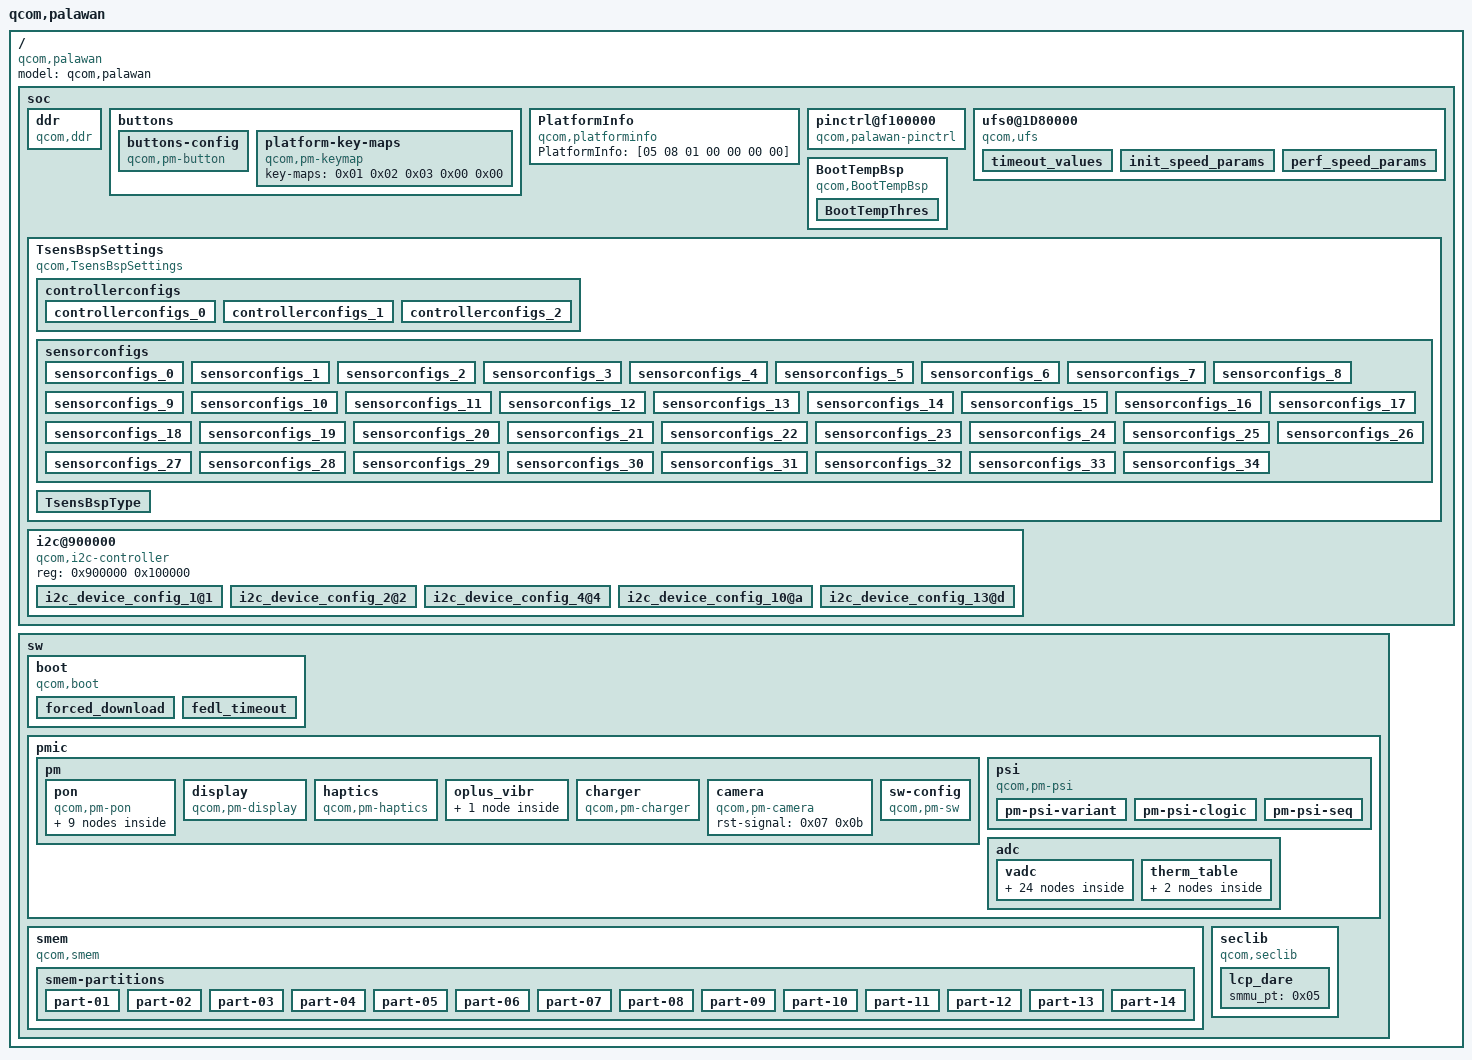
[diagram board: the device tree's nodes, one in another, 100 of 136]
/dts-v1/;

/ {
	compatible = "qcom,palawan";
	model = "qcom,palawan";
	#address-cells = <0x02>;
	#size-cells = <0x02>;

	soc {
		#address-cells = <0x01>;
		#size-cells = <0x01>;
		phandle = <0x02>;

		ddr {
			compatible = "qcom,ddr";
			print_severity = <0x2012>;
			ddr_log_level = <0x00>;
			ddr_trng_always_en = <0x00>;
			extnd_term_log_flag = <0x01>;
			ddr_tr_led_flag = <0x00>;
			ddr_boot_freq = <0x1fef00>;
		};

		buttons {
			phandle = <0x03>;

			buttons-config {
				compatible = "qcom,pm-button";
				gpio-configs = <0x00 0x01 0x01 0x05 0x00 0x01 0x00 0x00>;
			};

			platform-key-maps {
				compatible = "qcom,pm-keymap";
				key-maps = <0x01 0x02 0x03 0x00 0x00>;
			};
		};

		PlatformInfo {
			compatible = "qcom,platforminfo";
			PlatformInfo = [05 08 01 00 00 00 00];
		};

		pinctrl@f100000 {
			compatible = "qcom,palawan-pinctrl";
			reg = <0xf100000 0x100000>;
			ngpios = <0xb2>;
			width = <0x1000>;
			id = <0x00>;
			version = <0x01>;
			gpio-controller;
			#gpio-cells = <0x02>;
			phandle = <0x04>;
		};

		ufs0@1D80000 {
			compatible = "qcom,ufs";
			reg = <0x1d80000 0x7000>;
			EnableLogging = [00];
			FUA_Value = [01];
			LinkStartupRetryCount = [05];
			BatteryThresholdMv = <0xe10>;
			phandle = <0x05>;

			timeout_values {
				fDeviceInitTimeoutUs = <0x2625a0>;
				UTRDPollTimeoutUs = <0x1c9c380>;
			};

			init_speed_params {
				EnableHighSpeed = [01];
				NumGears = [05];
				NumLanes = [02];
				Rate = [02];
			};

			perf_speed_params {
				EnableHighSpeed = [01];
				NumGears = [05];
				NumLanes = [02];
				Rate = [02];
			};
		};

		BootTempBsp {
			compatible = "qcom,BootTempBsp";

			BootTempThres {
				nUpperThresholdDegC = <0x96>;
				nLowerThresholdDegC = <0xffffff6a>;
				uMaxNumIterations = <0x28>;
				uWaitPerIterationMicroSec = <0x7a120>;
				uSensor = <0x00>;
			};
		};

		TsensBspSettings {
			compatible = "qcom,TsensBspSettings";

			controllerconfigs {

				controllerconfigs_0 {
					pucTsensSROTPhys = <0x00 0xc222000>;
					pucTsensTMPhys = <0x00 0xc228000>;
					pauTbcbReqs = <0x00 0x00>;
					uTsensSROTSize = <0x1000>;
					uTsensTMSize = <0x1000>;
					uNumTbcbClients = <0x00>;
					uPeriodActive = <0x00>;
					uPeriodSleep = <0x40>;
					uTSControl = <0x20000000>;
					uTSConfig = <0x00>;
					uSidebandEnMask = <0x3fff>;
					uWatchdogLoadVal = <0x267a>;
					uZeroCEnMask = <0x3fff>;
					nsZeroCSetDeciDegC = [00 32];
					nsZeroCResetDeciDegC = [00 64];
					bPSHoldResetEn = [01];
					bAutoAdjustPeriod = [01];
					bStandAlone = [00];
					bPWMEn = [00];
					bWatchdogEn = [01];
					bWatchdogResetEn = [01];
				};

				controllerconfigs_1 {
					pucTsensSROTPhys = <0x00 0xc223000>;
					pucTsensTMPhys = <0x00 0xc229000>;
					pauTbcbReqs = <0x00 0x00>;
					uTsensSROTSize = <0x1000>;
					uTsensTMSize = <0x1000>;
					uNumTbcbClients = <0x00>;
					uPeriodActive = <0x00>;
					uPeriodSleep = <0x40>;
					uTSControl = <0x20000000>;
					uTSConfig = <0x00>;
					uSidebandEnMask = <0xffff>;
					uWatchdogLoadVal = <0x267a>;
					uZeroCEnMask = <0xffff>;
					nsZeroCSetDeciDegC = [00 32];
					nsZeroCResetDeciDegC = [00 64];
					bPSHoldResetEn = [01];
					bAutoAdjustPeriod = [01];
					bStandAlone = [00];
					bPWMEn = [00];
					bWatchdogEn = [01];
					bWatchdogResetEn = [01];
				};

				controllerconfigs_2 {
					pucTsensSROTPhys = <0x00 0xc224000>;
					pucTsensTMPhys = <0x00 0xc22a000>;
					pauTbcbReqs = <0x00 0x00>;
					uTsensSROTSize = <0x1000>;
					uTsensTMSize = <0x1000>;
					uNumTbcbClients = <0x00>;
					uPeriodActive = <0x00>;
					uPeriodSleep = <0x40>;
					uTSControl = <0x20000000>;
					uTSConfig = <0x00>;
					uSidebandEnMask = <0x1f>;
					uWatchdogLoadVal = <0x267a>;
					uZeroCEnMask = <0x1f>;
					nsZeroCSetDeciDegC = [00 32];
					nsZeroCResetDeciDegC = [00 64];
					bPSHoldResetEn = [01];
					bAutoAdjustPeriod = [01];
					bStandAlone = [00];
					bPWMEn = [00];
					bWatchdogEn = [01];
					bWatchdogResetEn = [01];
				};
			};

			sensorconfigs {

				sensorconfigs_0 {
					eCal = <0x00>;
					nsCalPoint1CodeDefault = [01 e0];
					nsCalPoint2CodeDefault = [02 ca];
					nsThresholdMinDeciDegC = [7f ff];
					nsThresholdLowerDeciDegC = [7f ff];
					nsThresholdUpperDeciDegC = [7f ff];
					nsThresholdCriticalDeciDegC = [7f ff];
					nsThresholdMaxDeciDegC = [04 b0];
					controller = [00];
					ucChannel = [00];
					ucSensorID = [00];
					ucFuseIdx = [00];
				};

				sensorconfigs_1 {
					eCal = <0x00>;
					nsCalPoint1CodeDefault = [01 e0];
					nsCalPoint2CodeDefault = [02 ca];
					nsThresholdMinDeciDegC = [7f ff];
					nsThresholdLowerDeciDegC = [7f ff];
					nsThresholdUpperDeciDegC = [7f ff];
					nsThresholdCriticalDeciDegC = [7f ff];
					nsThresholdMaxDeciDegC = [04 b0];
					controller = [00];
					ucChannel = [01];
					ucSensorID = [01];
					ucFuseIdx = [01];
				};

				sensorconfigs_2 {
					eCal = <0x00>;
					nsCalPoint1CodeDefault = [01 e0];
					nsCalPoint2CodeDefault = [02 ca];
					nsThresholdMinDeciDegC = [7f ff];
					nsThresholdLowerDeciDegC = [7f ff];
					nsThresholdUpperDeciDegC = [7f ff];
					nsThresholdCriticalDeciDegC = [7f ff];
					nsThresholdMaxDeciDegC = [04 b0];
					controller = [00];
					ucChannel = [02];
					ucSensorID = [02];
					ucFuseIdx = [02];
				};

				sensorconfigs_3 {
					eCal = <0x00>;
					nsCalPoint1CodeDefault = [01 e0];
					nsCalPoint2CodeDefault = [02 ca];
					nsThresholdMinDeciDegC = [7f ff];
					nsThresholdLowerDeciDegC = [7f ff];
					nsThresholdUpperDeciDegC = [7f ff];
					nsThresholdCriticalDeciDegC = [7f ff];
					nsThresholdMaxDeciDegC = [04 b0];
					controller = [00];
					ucChannel = [03];
					ucSensorID = [03];
					ucFuseIdx = [03];
				};

				sensorconfigs_4 {
					eCal = <0x00>;
					nsCalPoint1CodeDefault = [01 e0];
					nsCalPoint2CodeDefault = [02 ca];
					nsThresholdMinDeciDegC = [7f ff];
					nsThresholdLowerDeciDegC = [7f ff];
					nsThresholdUpperDeciDegC = [7f ff];
					nsThresholdCriticalDeciDegC = [7f ff];
					nsThresholdMaxDeciDegC = [04 b0];
					controller = [00];
					ucChannel = [04];
					ucSensorID = [04];
					ucFuseIdx = [04];
				};

				sensorconfigs_5 {
					eCal = <0x00>;
					nsCalPoint1CodeDefault = [01 e0];
					nsCalPoint2CodeDefault = [02 ca];
					nsThresholdMinDeciDegC = [7f ff];
					nsThresholdLowerDeciDegC = [7f ff];
					nsThresholdUpperDeciDegC = [7f ff];
					nsThresholdCriticalDeciDegC = [7f ff];
					nsThresholdMaxDeciDegC = [04 b0];
					controller = [00];
					ucChannel = [05];
					ucSensorID = [05];
					ucFuseIdx = [05];
				};

				sensorconfigs_6 {
					eCal = <0x00>;
					nsCalPoint1CodeDefault = [01 e0];
					nsCalPoint2CodeDefault = [02 ca];
					nsThresholdMinDeciDegC = [7f ff];
					nsThresholdLowerDeciDegC = [7f ff];
					nsThresholdUpperDeciDegC = [7f ff];
					nsThresholdCriticalDeciDegC = [7f ff];
					nsThresholdMaxDeciDegC = [04 b0];
					controller = [00];
					ucChannel = [06];
					ucSensorID = [06];
					ucFuseIdx = [06];
				};

				sensorconfigs_7 {
					eCal = <0x00>;
					nsCalPoint1CodeDefault = [01 e0];
					nsCalPoint2CodeDefault = [02 ca];
					nsThresholdMinDeciDegC = [7f ff];
					nsThresholdLowerDeciDegC = [7f ff];
					nsThresholdUpperDeciDegC = [7f ff];
					nsThresholdCriticalDeciDegC = [7f ff];
					nsThresholdMaxDeciDegC = [04 b0];
					controller = [00];
					ucChannel = [07];
					ucSensorID = [07];
					ucFuseIdx = [07];
				};

				sensorconfigs_8 {
					eCal = <0x00>;
					nsCalPoint1CodeDefault = [01 e0];
					nsCalPoint2CodeDefault = [02 ca];
					nsThresholdMinDeciDegC = [7f ff];
					nsThresholdLowerDeciDegC = [7f ff];
					nsThresholdUpperDeciDegC = [7f ff];
					nsThresholdCriticalDeciDegC = [7f ff];
					nsThresholdMaxDeciDegC = [04 b0];
					controller = [00];
					ucChannel = [08];
					ucSensorID = [08];
					ucFuseIdx = [08];
				};

				sensorconfigs_9 {
					eCal = <0x00>;
					nsCalPoint1CodeDefault = [01 e0];
					nsCalPoint2CodeDefault = [02 ca];
					nsThresholdMinDeciDegC = [7f ff];
					nsThresholdLowerDeciDegC = [7f ff];
					nsThresholdUpperDeciDegC = [7f ff];
					nsThresholdCriticalDeciDegC = [7f ff];
					nsThresholdMaxDeciDegC = [04 b0];
					controller = [00];
					ucChannel = [09];
					ucSensorID = [09];
					ucFuseIdx = [09];
				};

				sensorconfigs_10 {
					eCal = <0x00>;
					nsCalPoint1CodeDefault = [01 e0];
					nsCalPoint2CodeDefault = [02 ca];
					nsThresholdMinDeciDegC = [7f ff];
					nsThresholdLowerDeciDegC = [7f ff];
					nsThresholdUpperDeciDegC = [7f ff];
					nsThresholdCriticalDeciDegC = [7f ff];
					nsThresholdMaxDeciDegC = [04 b0];
					controller = [00];
					ucChannel = [0a];
					ucSensorID = [0a];
					ucFuseIdx = [0a];
				};

				sensorconfigs_11 {
					eCal = <0x00>;
					nsCalPoint1CodeDefault = [01 e0];
					nsCalPoint2CodeDefault = [02 ca];
					nsThresholdMinDeciDegC = [7f ff];
					nsThresholdLowerDeciDegC = [7f ff];
					nsThresholdUpperDeciDegC = [7f ff];
					nsThresholdCriticalDeciDegC = [7f ff];
					nsThresholdMaxDeciDegC = [04 b0];
					controller = [00];
					ucChannel = [0b];
					ucSensorID = [0b];
					ucFuseIdx = [0b];
				};

				sensorconfigs_12 {
					eCal = <0x00>;
					nsCalPoint1CodeDefault = [01 e0];
					nsCalPoint2CodeDefault = [02 ca];
					nsThresholdMinDeciDegC = [7f ff];
					nsThresholdLowerDeciDegC = [7f ff];
					nsThresholdUpperDeciDegC = [7f ff];
					nsThresholdCriticalDeciDegC = [7f ff];
					nsThresholdMaxDeciDegC = [04 b0];
					controller = [00];
					ucChannel = [0c];
					ucSensorID = [0c];
					ucFuseIdx = [0c];
				};

				sensorconfigs_13 {
					eCal = <0x00>;
					nsCalPoint1CodeDefault = [01 e0];
					nsCalPoint2CodeDefault = [02 ca];
					nsThresholdMinDeciDegC = [7f ff];
					nsThresholdLowerDeciDegC = [7f ff];
					nsThresholdUpperDeciDegC = [7f ff];
					nsThresholdCriticalDeciDegC = [7f ff];
					nsThresholdMaxDeciDegC = [04 b0];
					controller = [00];
					ucChannel = [0d];
					ucSensorID = [0d];
					ucFuseIdx = [0d];
				};

				sensorconfigs_14 {
					eCal = <0x00>;
					nsCalPoint1CodeDefault = [01 e0];
					nsCalPoint2CodeDefault = [02 ca];
					nsThresholdMinDeciDegC = [7f ff];
					nsThresholdLowerDeciDegC = [7f ff];
					nsThresholdUpperDeciDegC = [7f ff];
					nsThresholdCriticalDeciDegC = [7f ff];
					nsThresholdMaxDeciDegC = [04 b0];
					controller = [01];
					ucChannel = [00];
					ucSensorID = [00];
					ucFuseIdx = [0e];
				};

				sensorconfigs_15 {
					eCal = <0x00>;
					nsCalPoint1CodeDefault = [01 e0];
					nsCalPoint2CodeDefault = [02 ca];
					nsThresholdMinDeciDegC = [7f ff];
					nsThresholdLowerDeciDegC = [7f ff];
					nsThresholdUpperDeciDegC = [7f ff];
					nsThresholdCriticalDeciDegC = [7f ff];
					nsThresholdMaxDeciDegC = [04 b0];
					controller = [01];
					ucChannel = [01];
					ucSensorID = [01];
					ucFuseIdx = [0f];
				};

				sensorconfigs_16 {
					eCal = <0x00>;
					nsCalPoint1CodeDefault = [01 e0];
					nsCalPoint2CodeDefault = [02 ca];
					nsThresholdMinDeciDegC = [7f ff];
					nsThresholdLowerDeciDegC = [7f ff];
					nsThresholdUpperDeciDegC = [7f ff];
					nsThresholdCriticalDeciDegC = [7f ff];
					nsThresholdMaxDeciDegC = [04 b0];
					controller = [01];
					ucChannel = [02];
					ucSensorID = [02];
					ucFuseIdx = [10];
				};

				sensorconfigs_17 {
					eCal = <0x00>;
					nsCalPoint1CodeDefault = [01 e0];
					nsCalPoint2CodeDefault = [02 ca];
					nsThresholdMinDeciDegC = [7f ff];
					nsThresholdLowerDeciDegC = [7f ff];
					nsThresholdUpperDeciDegC = [7f ff];
					nsThresholdCriticalDeciDegC = [7f ff];
					nsThresholdMaxDeciDegC = [04 b0];
					controller = [01];
					ucChannel = [03];
					ucSensorID = [03];
					ucFuseIdx = [11];
				};

				sensorconfigs_18 {
					eCal = <0x00>;
					nsCalPoint1CodeDefault = [01 e0];
					nsCalPoint2CodeDefault = [02 ca];
					nsThresholdMinDeciDegC = [7f ff];
					nsThresholdLowerDeciDegC = [7f ff];
					nsThresholdUpperDeciDegC = [7f ff];
					nsThresholdCriticalDeciDegC = [7f ff];
					nsThresholdMaxDeciDegC = [04 b0];
					controller = [01];
					ucChannel = [04];
					ucSensorID = [04];
					ucFuseIdx = [12];
				};

				sensorconfigs_19 {
					eCal = <0x00>;
					nsCalPoint1CodeDefault = [01 e0];
					nsCalPoint2CodeDefault = [02 ca];
					nsThresholdMinDeciDegC = [7f ff];
					nsThresholdLowerDeciDegC = [7f ff];
					nsThresholdUpperDeciDegC = [7f ff];
					nsThresholdCriticalDeciDegC = [7f ff];
					nsThresholdMaxDeciDegC = [04 b0];
					controller = [01];
					ucChannel = [05];
					ucSensorID = [05];
					ucFuseIdx = [13];
				};

				sensorconfigs_20 {
					eCal = <0x00>;
					nsCalPoint1CodeDefault = [01 e0];
					nsCalPoint2CodeDefault = [02 ca];
					nsThresholdMinDeciDegC = [7f ff];
					nsThresholdLowerDeciDegC = [7f ff];
					nsThresholdUpperDeciDegC = [7f ff];
					nsThresholdCriticalDeciDegC = [7f ff];
					nsThresholdMaxDeciDegC = [04 b0];
					controller = [01];
					ucChannel = [06];
					ucSensorID = [06];
					ucFuseIdx = [14];
				};

				sensorconfigs_21 {
					eCal = <0x00>;
					nsCalPoint1CodeDefault = [01 e0];
					nsCalPoint2CodeDefault = [02 ca];
					nsThresholdMinDeciDegC = [7f ff];
					nsThresholdLowerDeciDegC = [7f ff];
					nsThresholdUpperDeciDegC = [7f ff];
					nsThresholdCriticalDeciDegC = [7f ff];
					nsThresholdMaxDeciDegC = [04 b0];
					controller = [01];
					ucChannel = [07];
					ucSensorID = [07];
					ucFuseIdx = [15];
				};

				sensorconfigs_22 {
					eCal = <0x00>;
					nsCalPoint1CodeDefault = [01 e0];
					nsCalPoint2CodeDefault = [02 ca];
					nsThresholdMinDeciDegC = [7f ff];
					nsThresholdLowerDeciDegC = [7f ff];
					nsThresholdUpperDeciDegC = [7f ff];
					nsThresholdCriticalDeciDegC = [7f ff];
					nsThresholdMaxDeciDegC = [04 b0];
					controller = [01];
					ucChannel = [08];
					ucSensorID = [08];
					ucFuseIdx = [16];
				};

				sensorconfigs_23 {
					eCal = <0x00>;
					nsCalPoint1CodeDefault = [01 e0];
					nsCalPoint2CodeDefault = [02 ca];
					nsThresholdMinDeciDegC = [7f ff];
					nsThresholdLowerDeciDegC = [7f ff];
					nsThresholdUpperDeciDegC = [7f ff];
					nsThresholdCriticalDeciDegC = [7f ff];
					nsThresholdMaxDeciDegC = [04 b0];
					controller = [01];
					ucChannel = [09];
					ucSensorID = [09];
					ucFuseIdx = [17];
				};

				sensorconfigs_24 {
					eCal = <0x00>;
					nsCalPoint1CodeDefault = [01 e0];
					nsCalPoint2CodeDefault = [02 ca];
					nsThresholdMinDeciDegC = [7f ff];
					nsThresholdLowerDeciDegC = [7f ff];
					nsThresholdUpperDeciDegC = [7f ff];
					nsThresholdCriticalDeciDegC = [7f ff];
					nsThresholdMaxDeciDegC = [04 b0];
					controller = [01];
					ucChannel = [0a];
					ucSensorID = [0a];
					ucFuseIdx = [18];
				};

				sensorconfigs_25 {
					eCal = <0x00>;
					nsCalPoint1CodeDefault = [01 e0];
					nsCalPoint2CodeDefault = [02 ca];
					nsThresholdMinDeciDegC = [7f ff];
					nsThresholdLowerDeciDegC = [7f ff];
					nsThresholdUpperDeciDegC = [7f ff];
					nsThresholdCriticalDeciDegC = [7f ff];
					nsThresholdMaxDeciDegC = [04 b0];
					controller = [01];
					ucChannel = [0b];
					ucSensorID = [0b];
					ucFuseIdx = [19];
				};

				sensorconfigs_26 {
					eCal = <0x00>;
					nsCalPoint1CodeDefault = [01 e0];
					nsCalPoint2CodeDefault = [02 ca];
					nsThresholdMinDeciDegC = [7f ff];
					nsThresholdLowerDeciDegC = [7f ff];
					nsThresholdUpperDeciDegC = [7f ff];
					nsThresholdCriticalDeciDegC = [7f ff];
					nsThresholdMaxDeciDegC = [04 b0];
					controller = [01];
					ucChannel = [0c];
					ucSensorID = [0c];
					ucFuseIdx = [1a];
				};

				sensorconfigs_27 {
					eCal = <0x00>;
					nsCalPoint1CodeDefault = [01 e0];
					nsCalPoint2CodeDefault = [02 ca];
					nsThresholdMinDeciDegC = [7f ff];
					nsThresholdLowerDeciDegC = [7f ff];
					nsThresholdUpperDeciDegC = [7f ff];
					nsThresholdCriticalDeciDegC = [7f ff];
					nsThresholdMaxDeciDegC = [04 b0];
					controller = [01];
					ucChannel = [0d];
					ucSensorID = [0d];
					ucFuseIdx = [1b];
				};

				sensorconfigs_28 {
					eCal = <0x00>;
					nsCalPoint1CodeDefault = [01 e0];
					nsCalPoint2CodeDefault = [02 ca];
					nsThresholdMinDeciDegC = [7f ff];
					nsThresholdLowerDeciDegC = [7f ff];
					nsThresholdUpperDeciDegC = [7f ff];
					nsThresholdCriticalDeciDegC = [7f ff];
					nsThresholdMaxDeciDegC = [04 b0];
					controller = [01];
					ucChannel = [0e];
					ucSensorID = [0e];
					ucFuseIdx = [1c];
				};

				sensorconfigs_29 {
					eCal = <0x00>;
					nsCalPoint1CodeDefault = [01 e0];
					nsCalPoint2CodeDefault = [02 ca];
					nsThresholdMinDeciDegC = [7f ff];
					nsThresholdLowerDeciDegC = [7f ff];
					nsThresholdUpperDeciDegC = [7f ff];
					nsThresholdCriticalDeciDegC = [7f ff];
					nsThresholdMaxDeciDegC = [04 b0];
					controller = [01];
					ucChannel = [0f];
					ucSensorID = [0f];
					ucFuseIdx = [1d];
				};

				sensorconfigs_30 {
					eCal = <0x00>;
					nsCalPoint1CodeDefault = [01 e0];
					nsCalPoint2CodeDefault = [02 ca];
					nsThresholdMinDeciDegC = [7f ff];
					nsThresholdLowerDeciDegC = [7f ff];
					nsThresholdUpperDeciDegC = [7f ff];
					nsThresholdCriticalDeciDegC = [7f ff];
					nsThresholdMaxDeciDegC = [04 b0];
					controller = [02];
					ucChannel = [00];
					ucSensorID = [00];
					ucFuseIdx = [1e];
				};

				sensorconfigs_31 {
					eCal = <0x00>;
					nsCalPoint1CodeDefault = [01 e0];
					nsCalPoint2CodeDefault = [02 ca];
					nsThresholdMinDeciDegC = [7f ff];
					nsThresholdLowerDeciDegC = [7f ff];
					nsThresholdUpperDeciDegC = [7f ff];
					nsThresholdCriticalDeciDegC = [7f ff];
					nsThresholdMaxDeciDegC = [04 b0];
					controller = [02];
					ucChannel = [01];
					ucSensorID = [01];
					ucFuseIdx = [1f];
				};

				sensorconfigs_32 {
					eCal = <0x00>;
					nsCalPoint1CodeDefault = [01 e0];
					nsCalPoint2CodeDefault = [02 ca];
					nsThresholdMinDeciDegC = [7f ff];
					nsThresholdLowerDeciDegC = [7f ff];
					nsThresholdUpperDeciDegC = [7f ff];
					nsThresholdCriticalDeciDegC = [7f ff];
					nsThresholdMaxDeciDegC = [04 b0];
					controller = [02];
					ucChannel = [02];
					ucSensorID = [02];
					ucFuseIdx = [20];
				};

				sensorconfigs_33 {
					eCal = <0x00>;
					nsCalPoint1CodeDefault = [01 e0];
					nsCalPoint2CodeDefault = [02 ca];
					nsThresholdMinDeciDegC = [7f ff];
					nsThresholdLowerDeciDegC = [7f ff];
					nsThresholdUpperDeciDegC = [7f ff];
					nsThresholdCriticalDeciDegC = [7f ff];
					nsThresholdMaxDeciDegC = [04 b0];
					controller = [02];
					ucChannel = [03];
					ucSensorID = [03];
					ucFuseIdx = [21];
				};

				sensorconfigs_34 {
					eCal = <0x00>;
					nsCalPoint1CodeDefault = [01 e0];
					nsCalPoint2CodeDefault = [02 ca];
					nsThresholdMinDeciDegC = [7f ff];
					nsThresholdLowerDeciDegC = [7f ff];
					nsThresholdUpperDeciDegC = [7f ff];
					nsThresholdCriticalDeciDegC = [7f ff];
					nsThresholdMaxDeciDegC = [04 b0];
					controller = [02];
					ucChannel = [04];
					ucSensorID = [04];
					ucFuseIdx = [22];
				};
			};

			TsensBspType {
				uNumControllers = <0x03>;
				uNumSensors = <0x23>;
				uSensorConvTime_us = <0x1e>;
				nCalPoint1DeciDegC = <0x12c>;
				nCalPoint2DeciDegC = <0x4b0>;
				uShift = <0x0a>;
			};
		};

		i2c@900000 {
			#address-cells = <0x01>;
			#size-cells = <0x00>;
			compatible = "qcom,i2c-controller";
			reg = <0x900000 0x100000>;

			i2c_device_config_1@1 {
				reg = <0x01>;
				status = "okay";
				core_base_addr = <0xa00000>;
				common_base_addr = <0xac0000>;
				core_offset = <0x80000>;
				qupv3_instance = [00];
				core_index = [01];
				se_index = [00];
				gpi_index = [00];
				core_irq = [00];
				polled_mode = [01];
				i2c_hub = [00];
				min_data_length_for_dma = [00];
				scl_encoding = <0x40018351>;
				sda_encoding = <0x40018341>;
				tcsr_reg_offset = <0x00>;
				tcsr_base_addr = <0x1fc0000>;
				tcsr_reg_value = <0x00>;
				se_clock = "gcc_qupv3_wrap0_s0_clk";
			};

			i2c_device_config_2@2 {
				reg = <0x02>;
				status = "okay";
				core_base_addr = <0xa00000>;
				common_base_addr = <0xac0000>;
				core_offset = "", "\b@";
				qupv3_instance = [00];
				core_index = [02];
				se_index = [01];
				gpi_index = [00];
				core_irq = [00];
				polled_mode = [01];
				i2c_hub = [00];
				min_data_length_for_dma = [00];
				scl_encoding = <0x18051>;
				sda_encoding = <0x18041>;
				tcsr_reg_offset = <0x00>;
				tcsr_base_addr = <0x1fc0000>;
				tcsr_reg_value = <0x00>;
				se_clock = "gcc_qupv3_wrap0_s1_clk";
			};

			i2c_device_config_4@4 {
				reg = <0x04>;
				status = "okay";
				core_base_addr = <0xa00000>;
				common_base_addr = <0xac0000>;
				core_offset = <0x8c000>;
				qupv3_instance = [00];
				core_index = [04];
				se_index = [03];
				gpi_index = [03];
				core_irq = [00];
				polled_mode = [01];
				i2c_hub = [00];
				min_data_length_for_dma = [00];
				scl_encoding = <0x400180d2>;
				sda_encoding = <0x400180c2>;
				tcsr_reg_offset = <0x00>;
				tcsr_base_addr = <0x1fc0000>;
				tcsr_reg_value = <0x00>;
				se_clock = "gcc_qupv3_wrap0_s3_clk";
			};

			i2c_device_config_10@a {
				reg = <0x0a>;
				status = "okay";
				core_base_addr = <0x800000>;
				common_base_addr = <0x8c0000>;
				core_offset = "", "\b@";
				qupv3_instance = [01];
				core_index = [0a];
				se_index = [01];
				gpi_index = [09];
				core_irq = [00];
				polled_mode = [01];
				i2c_hub = [00];
				min_data_length_for_dma = [00];
				scl_encoding = <0x18251>;
				sda_encoding = <0x18241>;
				tcsr_reg_offset = <0x00>;
				tcsr_base_addr = <0x1fc0000>;
				tcsr_reg_value = <0x00>;
				se_clock = "gcc_qupv3_wrap1_s1_clk";
			};

			i2c_device_config_13@d {
				reg = <0x0d>;
				status = "okay";
				core_base_addr = <0x800000>;
				common_base_addr = <0x8c0000>;
				core_offset = <0x90000>;
				qupv3_instance = [01];
				core_index = [0d];
				se_index = [04];
				gpi_index = [0c];
				core_irq = [00];
				polled_mode = [01];
				i2c_hub = [00];
				min_data_length_for_dma = [00];
				scl_encoding = <0x18b11>;
				sda_encoding = <0x18b01>;
				tcsr_reg_offset = <0x00>;
				tcsr_base_addr = <0x1fc0000>;
				tcsr_reg_value = <0x00>;
				se_clock = "gcc_qupv3_wrap1_s4_clk";
			};
		};
	};

	sw {
		phandle = <0x06>;

		boot {
			compatible = "qcom,boot";
			config = <0x00 0x00 0x00>;
			force_dump_to_usb = <0x00>;
			test_mode = <0x00>;
			xbl_sc_wdog = <0x01>;
			xbl_ramdump_wdog = <0x00>;
			skip_ddr_init_in_EDL = <0x00>;
			vibration = <0x00>;
			save_logs_to_media = <0x01>;

			forced_download {
				feature = <0x01>;
				check_usb_option = <0x02>;
				check_dp_timeout = <0x2710>;
				ignore_pwr_key = <0x01>;
			};

			fedl_timeout {
				ver = <0x01>;
				action = <0x01>;
			};
		};

		pmic {

			pm {
				phandle = <0x07>;

				pon {
					compatible = "qcom,pm-pon";

					pshold {
						enable = [00];
						reset-type = [01];
					};

					smpl {
						enable = [01];
						smpl-delay = <0x320>;
					};

					s2-kpdpwr {
						enable = [00];
						reset-type = [00];
						s1-ms = <0x2810>;
						s2-ms = <0x7d0>;
					};

					s2-kpdpwr-resin {
						enable = [01];
						reset-type = [01];
						s1-ms = <0x2810>;
						s2-ms = <0x7d0>;
					};

					s2-resin {
						enable = [00];
						reset-type = [01];
						s1-ms = <0x2810>;
						s2-ms = <0x7d0>;
					};

					s3-reset {
						enable = [01];
						s3-src = [02];
						timer-value-ms = <0x3e80>;
					};

					uvlo-config {
						config-value = <0x00>;
					};

					ovlo-config {
						config-value = <0x00>;
					};

					long-pwrkey-dbnc-chk {
						dbnc-time-ms = <0x898>;
						chk-at = [01];
					};
				};

				display {
					compatible = "qcom,pm-display";
					swire-map = [07];
					apply-default-volt = [00];
					default-elvss = <0xfffff060>;
					default-elvdd = <0x11f8>;
					default-oledb = <0x1900>;
				};

				haptics {
					compatible = "qcom,pm-haptics";
					ext-boost-vdd = <0x01>;
					vmax-hdrm = <0x0a>;
					vmax-mv = <0x578>;
					tlra-ol = <0x477>;
					autores-cfg = <0x01>;
					vbatt-min = <0x00>;
					boost-cfg-bob = <0x00>;
					lra-resistance = <0x24>;
					swr-io-volt = <0x00>;
				};

				oplus_vibr {

					vibr_0 {
						support_project = <0x5cfb 0x5d39 0x5d3a 0x5c39 0x606f 0x5c46 0x5ca6 0x5e93 0x5e94 0x60e1>;
						vibr_min_vbatt = <0x1900>;
						vibr_scheme = <0x03>;
						instance = <0x04>;
						reset_gpio = <0x93>;
						device_type = <0x00>;
					};
				};

				charger {
					compatible = "qcom,pm-charger";
					parallel-charger = [00];
					charger-pmic-index = <0x07>;
					charger-bus-index = <0x00>;
					loader-dbc-threshold = <0x00>;
					dbc-sdp-thd-inc = <0x64>;
					skip-loader-dbc = [00];
					core-dbc-threshold = <0x00>;
					skip-core-dbc = [01];
					dbc-max-timer-sec = <0x00>;
					uv-oc-1s-threshold = <0x960>;
					uv-oc-2s-threshold = <0x12c0>;
					apply-ichg-fs = [01];
					ichg-fs = <0x00>;
					batt-2s-option = <0x01>;
					batt-1s2p-id2 = [00];
					batt-1s2p-therm2 = [00];
					too-hot-afp-threshold = <0x48>;
					apply-too-hot-afp = [00];
					too-cold-afp-threshold = <0xfffffff1>;
					apply-too-cold-afp = [00];
					apply-boot-wo-batt = [01];
					boot-wo-batt = [01];
					icl-boot-wo-batt = <0x3e8>;
					apply-float-voltage = [01];
					float-voltage-mv = <0x1176>;
					apply-pre-charge-current = [01];
					pre-charge-ma = <0x258>;
					apply-fast-charge-current = [01];
					fast-charge-ma = <0x258>;
					apply-icl = [01];
					icl-ma = <0x7d0>;
					apply-float-charger-icl = [00];
					float-charger-icl-ma = <0x3e8>;
					apply-vsysmin = [01];
					vsysmin = <0xd48>;
					usb-suspend = [00];
					wls-usb-prior-swap = <0x01>;
					batt-detect-src = <0x00>;
					max-dbg-board-id = <0x2af8>;
					min-dbg-board-id = <0xbb8>;
					detect-jig-by-therm = [00];
					max-therm = <0x30c>;
					min-therm = <0x50>;
					jig-icl-ma = <0x5dc>;
					uvp-recover-delay = <0xbb8>;
					ignore-temp-in-dbc = [01];
					batt-therm-pull-up = <0x01>;
					ibat-via-ext-sense = [01];
					ext-rsns-adc-scale = <0x00>;
					ext-rsns-installed = <0x00>;
					vbat-thd-rtc-pon = <0xe10>;
					vsys-min-recover-mv = <0x11f8>;
					vflt-recover-mv = <0x1194>;
				};

				camera {
					compatible = "qcom,pm-camera";
					rst-signal = <0x07 0x0b>;
				};

				sw-config {
					compatible = "qcom,pm-sw";
					verbose = <0x00>;
					driver-post-init = <0x65 0x00 0x00 0x03 0x03 0x01 0x00 0x0c 0x04 0x708 0x01 0x00 0x01 0x0d 0xbb8 0x01 0x00 0x01 0x0e 0xaf0 0x07 0x00 0x00 0x00 0x01 0x3f 0x00 0x07 0x02 0x01 0x3f 0x00 0x07 0x03 0x01 0x3d 0x00 0x03 0x04 0x01 0x3f 0x00 0x03 0x04 0x01 0x43 0x00 0x03 0x04 0x05 0x3e 0x00 0x03 0x04 0x00 0x3c 0x00 0x03 0x04 0x01 0x64 0x00 0x00 0x00 0x0a>;
					apply-rsns-trim = <0x00>;
					rsns-trim-value = <0x00>;
					primming-enable = [00];
					multi-card-tray-config = [00];
					vdd-mdm-apq-ctrl = [00];
					device-pre-init = <0x85 0x00 0x00 0x00 0x00>;
					use-wlan-dt = [00];
					batt-log-param = [00];
				};
			};

			psi {
				compatible = "qcom,pm-psi";
				phandle = <0x08>;

				pm-psi-variant {
					major = [00 00];
					minor = [00 00];
				};

				pm-psi-clogic {
					clogic-version = <0x01>;
					clogic-data = <0x00 0x00 0x00 0x10 0xff 0x52 0x01>;
				};

				pm-psi-seq {
					opsi-settings-version = <0x01>;
					post-device-opsi = <0x00 0x00 0x04 0x00 0x00 0x00 0x00 0x00 0x00>;
				};
			};

			adc {
				phandle = <0x09>;

				vadc {
					phandle = <0x0a>;

					spmi-vadc {
						compatible = "qcom,spmi-vadc";
						use-interrupt = <0x00>;
						fullscale-code = <0x70e4>;
						fullscale-uV = <0x1c9c38>;
						fullratiometric-code = <0x4000>;
						read-timeout-uS = <0x7a120>;
						ldo-settling-uS = <0x43>;
						slave-id = <0x00>;
						peripheral-id = <0x90>;
						master-id = <0x00>;
						pmic-device = <0x00>;
						bus-id = <0x00>;
						therm-tbl = <0x01>;
						phandle = <0x0b>;

						vadc_ch_cfg {

							VPH_PWR {
								hw-channel = <0x8e>;
								settling-delay-uS = <0x00>;
								average-sample = <0x01>;
								decimation-ratio = <0x400>;
								cal-method = "abs ";
								scaling-factor = <0x01 0x03>;
								offset-factor = <0x00>;
								scaling-method = "tomV";
								pull-up-res = <0x00>;
								adc-sid = <0x07>;
								int-table;
							};

							PMIC_TEMP7 {
								hw-channel = <0x03>;
								settling-delay-uS = <0x00>;
								average-sample = <0x01>;
								decimation-ratio = <0x400>;
								cal-method = "abs ";
								scaling-factor = <0x01 0x01>;
								offset-factor = <0xfffbd598>;
								scaling-method = "xtuV";
								pull-up-res = <0x00>;
								adc-sid = <0x07>;
								int-table = "/sw/pmic/adc/therm_table/therm_tb2";
							};

							CHG_TEMP {
								hw-channel = <0x10>;
								settling-delay-uS = <0x00>;
								average-sample = <0x01>;
								decimation-ratio = <0x400>;
								cal-method = "abs ";
								scaling-factor = <0x01 0x01>;
								offset-factor = <0x00>;
								scaling-method = "tomV";
								pull-up-res = <0x00>;
								adc-sid = <0x07>;
								int-table;
							};

							BATT_THERM {
								hw-channel = <0x44>;
								settling-delay-uS = <0x64>;
								average-sample = <0x01>;
								decimation-ratio = <0x400>;
								cal-method = "raio";
								scaling-factor = <0x01 0x01>;
								offset-factor = <0xfffffeef>;
								scaling-method = "xtr ";
								pull-up-res = <0x186a0>;
								adc-sid = <0x07>;
								int-table = "/sw/pmic/adc/therm_table/therm_tb1";
							};

							BATT_THERM_PU_30K {
								hw-channel = <0x24>;
								settling-delay-uS = <0x64>;
								average-sample = <0x01>;
								decimation-ratio = <0x400>;
								cal-method = "raio";
								scaling-factor = <0x01 0x01>;
								offset-factor = <0xfffffeef>;
								scaling-method = "xtr ";
								pull-up-res = <0x7530>;
								adc-sid = <0x07>;
								int-table = "/sw/pmic/adc/therm_table/therm_tb1";
							};

							BATT_THERM_PU_400K {
								hw-channel = <0x64>;
								settling-delay-uS = <0x64>;
								average-sample = <0x01>;
								decimation-ratio = <0x400>;
								cal-method = "raio";
								scaling-factor = <0x01 0x01>;
								offset-factor = <0xfffffeef>;
								scaling-method = "xtr ";
								pull-up-res = <0x61a80>;
								adc-sid = <0x07>;
								int-table = "/sw/pmic/adc/therm_table/therm_tb1";
							};

							BATT_THERM_OHMS {
								hw-channel = <0x44>;
								settling-delay-uS = <0x64>;
								average-sample = <0x01>;
								decimation-ratio = <0x400>;
								cal-method = "raio";
								scaling-factor = <0x01 0x01>;
								offset-factor = <0x00>;
								scaling-method = "res ";
								pull-up-res = <0x186a0>;
								adc-sid = <0x07>;
								int-table;
							};

							BATT_ID_OHMS {
								hw-channel = <0x45>;
								settling-delay-uS = <0x64>;
								average-sample = <0x01>;
								decimation-ratio = <0x400>;
								cal-method = "raio";
								scaling-factor = <0x01 0x01>;
								offset-factor = <0x00>;
								scaling-method = "res ";
								pull-up-res = <0x186a0>;
								adc-sid = <0x07>;
								int-table;
							};

							BATT_ID_OHMS_PU_30K {
								hw-channel = <0x25>;
								settling-delay-uS = <0x64>;
								average-sample = <0x01>;
								decimation-ratio = <0x400>;
								cal-method = "raio";
								scaling-factor = <0x01 0x01>;
								offset-factor = <0x00>;
								scaling-method = "res ";
								pull-up-res = <0x7530>;
								adc-sid = <0x07>;
								int-table;
							};

							BATT_ID_OHMS_PU_400K {
								hw-channel = <0x65>;
								settling-delay-uS = <0x64>;
								average-sample = <0x01>;
								decimation-ratio = <0x400>;
								cal-method = "raio";
								scaling-factor = <0x01 0x01>;
								offset-factor = <0x00>;
								scaling-method = "res ";
								pull-up-res = <0x61a80>;
								adc-sid = <0x07>;
								int-table;
							};

							VBATT {
								hw-channel = <0x8f>;
								settling-delay-uS = <0x00>;
								average-sample = <0x01>;
								decimation-ratio = <0x400>;
								cal-method = "abs ";
								scaling-factor = <0x01 0x03>;
								offset-factor = <0x00>;
								scaling-method = "tomV";
								pull-up-res = <0x00>;
								adc-sid = <0x07>;
								int-table;
							};

							VBATT_2S {
								hw-channel = <0x8f>;
								settling-delay-uS = <0x00>;
								average-sample = <0x01>;
								decimation-ratio = <0x400>;
								cal-method = "abs ";
								scaling-factor = <0x01 0x06>;
								offset-factor = <0x00>;
								scaling-method = "tomV";
								pull-up-res = <0x00>;
								adc-sid = <0x07>;
								int-table;
							};

							VBATT_2S_MID {
								hw-channel = <0x96>;
								settling-delay-uS = <0x00>;
								average-sample = <0x01>;
								decimation-ratio = <0x400>;
								cal-method = "abs ";
								scaling-factor = <0x01 0x03>;
								offset-factor = <0x00>;
								scaling-method = "tomV";
								pull-up-res = <0x00>;
								adc-sid = <0x07>;
								int-table;
							};

							USB_IN {
								hw-channel = <0x11>;
								settling-delay-uS = <0x00>;
								average-sample = <0x01>;
								decimation-ratio = <0x400>;
								cal-method = "abs ";
								scaling-factor = <0x01 0x10>;
								offset-factor = <0x00>;
								scaling-method = "tomV";
								pull-up-res = <0x00>;
								adc-sid = <0x07>;
								int-table;
							};

							VWLS {
								hw-channel = <0x12>;
								settling-delay-uS = <0x00>;
								average-sample = <0x01>;
								decimation-ratio = <0x400>;
								cal-method = "abs ";
								scaling-factor = <0x01 0x10>;
								offset-factor = <0x00>;
								scaling-method = "tomV";
								pull-up-res = <0x00>;
								adc-sid = <0x07>;
								int-table;
							};

							USB_IN_I {
								hw-channel = <0x17>;
								settling-delay-uS = <0x00>;
								average-sample = <0x01>;
								decimation-ratio = <0x400>;
								cal-method = "abs ";
								scaling-factor = <0x08 0x19>;
								offset-factor = <0x00>;
								scaling-method = "tomV";
								pull-up-res = <0x00>;
								adc-sid = <0x07>;
								int-table;
							};

							OEM_VID {
								hw-channel = <0x4b>;
								settling-delay-uS = <0x64>;
								average-sample = <0x01>;
								decimation-ratio = <0x400>;
								cal-method = "raio";
								scaling-factor = <0x01 0x01>;
								offset-factor = <0x00>;
								scaling-method = "res ";
								pull-up-res = <0x186a0>;
								adc-sid = <0x01>;
								int-table;
							};

							PM8550_AMUX_THM4 {
								hw-channel = <0x47>;
								settling-delay-uS = <0x64>;
								average-sample = <0x01>;
								decimation-ratio = <0x400>;
								cal-method = "raio";
								scaling-factor = <0x01 0x01>;
								offset-factor = <0xfffffeef>;
								scaling-method = "xtr ";
								pull-up-res = <0x186a0>;
								adc-sid = <0x01>;
								int-table = "/sw/pmic/adc/therm_table/therm_tb1";
							};

							BATT_THERM_GPIO04 {
								hw-channel = <0x4b>;
								settling-delay-uS = <0x64>;
								average-sample = <0x01>;
								decimation-ratio = <0x400>;
								cal-method = "raio";
								scaling-factor = <0x01 0x01>;
								offset-factor = <0xfffffeef>;
								scaling-method = "xtr ";
								pull-up-res = <0x186a0>;
								adc-sid = <0x01>;
								int-table = "/sw/pmic/adc/therm_table/therm_tb1";
							};
						};

						vadc-avg-ch {
							ch-name = "XO_THERM_GPS";
							low-name = "XO_THERM_GPS_LOW";
							med-name = "XO_THERM_GPS_MED";
							high-name = "XO_THERM_GPS_HIGH";
							med-to-low = <0x1400>;
							low-to-med = <0x3c00>;
							high-to-med = <0x8000>;
							med-to-high = <0xa800>;
						};

						gpio-map {

							aux_pin1 {
								pmic-sid = <0x01>;
								gpio-num = <0x03>;
							};
						};
					};
				};

				therm_table {
					phandle = <0x01>;

					therm_tb1 {
						arr_id = <0x00>;
						table = <0x40dd78 0xe9 0x2dd9e4 0xee 0x20ca24 0xf3 0x17b588 0xf8 0x1152c4 0xfd 0xcc8a8 0x102 0x985e4 0x107 0x7286c 0x10c 0x56d10 0x111 0x425b8 0x116 0x331f8 0x11b 0x27ac4 0x120 0x1f018 0x125 0x186a0 0x12a 0x13560 0x12f 0xf6e0 0x134 0xc60c 0x139 0x9fc4 0x13e 0x81b0 0x143 0x69dc 0x148 0x56b8 0x14d 0x477c 0x152 0x3b60 0x157 0x3138 0x15c 0x2968 0x161 0x22ba 0x166 0x1d4c 0x16b 0x18d8 0x170 0x1522 0x175 0x120c 0x17a 0xf82 0x17f 0xd5c 0x184 0xb86 0x189 0xa00 0x18e>;
						phandle = <0x0c>;
					};

					therm_tb2 {
						arr_id = <0x01>;
						table = <0x69e24 0x34008 0x7380c 0x38e28 0x7d190 0x3dc48 0x86a4c 0x42a68 0x902a4 0x47888 0x99a34 0x4c6a8 0xa30fc 0x514c8 0xac760 0x562e8 0xb5c98 0x5b108 0xbf0a4 0x5ff28 0xc8384 0x64d48>;
						phandle = <0x0d>;
					};
				};
			};
		};

		smem {
			compatible = "qcom,smem";
			smem-vers = <0xc0000>;
			smem-toc-vers = <0x01>;
			smem-max-items = <0x28e>;

			smem-partitions {

				part-01 {
					size = <0x60000>;
					flags = <0x03>;
					host0 = <0x00>;
					host1 = <0x02>;
					size-cacheline = <0x20>;
					exclusion-sizes = <0x00 0x00 0x00 0x00>;
				};

				part-02 {
					size = <0x20000>;
					flags = <0x03>;
					host0 = <0x00>;
					host1 = <0x05>;
					size-cacheline = <0x20>;
					exclusion-sizes = <0x00 0x00 0x00 0x00>;
				};

				part-03 {
					size = <0x2000>;
					flags = <0x03>;
					host0 = <0x07>;
					host1 = <0x05>;
					size-cacheline = <0x20>;
					exclusion-sizes = <0x00 0x00 0x00 0x00>;
				};

				part-04 {
					size = <0x4000>;
					flags = <0x03>;
					host0 = <0x07>;
					host1 = <0x02>;
					size-cacheline = <0x20>;
					exclusion-sizes = <0x00 0x00 0x00 0x00>;
				};

				part-05 {
					size = <0x2000>;
					flags = <0x03>;
					host0 = <0x07>;
					host1 = <0x01>;
					size-cacheline = <0x20>;
					exclusion-sizes = <0x00 0x00 0x00 0x00>;
				};

				part-06 {
					size = <0x7c000>;
					flags = <0x03>;
					host0 = <0x00>;
					host1 = <0x01>;
					size-cacheline = <0x20>;
					exclusion-sizes = <0x00 0x00 0x00 0x00>;
				};

				part-07 {
					size = <0x30000>;
					flags = <0x03>;
					host0 = <0x01>;
					host1 = <0x02>;
					size-cacheline = <0x20>;
					exclusion-sizes = <0x00 0x00 0x00 0x00>;
				};

				part-08 {
					size = <0x2000>;
					flags = <0x03>;
					host0 = <0x00>;
					host1 = <0x0e>;
					size-cacheline = <0x20>;
					exclusion-sizes = <0x00 0x00 0x00 0x00>;
				};

				part-09 {
					size = <0x2000>;
					flags = <0x03>;
					host0 = <0x01>;
					host1 = <0x0e>;
					size-cacheline = <0x20>;
					exclusion-sizes = <0x00 0x00 0x00 0x00>;
				};

				part-10 {
					size = <0x4000>;
					flags = <0x03>;
					host0 = <0x0d>;
					host1 = <0x07>;
					size-cacheline = <0x20>;
					exclusion-sizes = <0x00 0x00 0x00 0x00>;
				};

				part-11 {
					size = <0x40000>;
					flags = <0x03>;
					host0 = <0x0d>;
					host1 = <0x00>;
					size-cacheline = <0x20>;
					exclusion-sizes = <0x00 0x00 0x00 0x00>;
				};

				part-12 {
					size = <0x20000>;
					flags = <0x03>;
					host0 = <0x0d>;
					host1 = <0x01>;
					size-cacheline = <0x20>;
					exclusion-sizes = <0x00 0x00 0x00 0x00>;
				};

				part-13 {
					size = <0x20000>;
					flags = <0x03>;
					host0 = <0x0d>;
					host1 = <0x02>;
					size-cacheline = <0x20>;
					exclusion-sizes = <0x00 0x00 0x00 0x00>;
				};

				part-14 {
					size = <0x00>;
					flags = <0x00>;
					host0 = <0xffff>;
					host1 = <0xffff>;
					size-cacheline = <0x00>;
					exclusion-sizes = <0x00 0x00 0x00 0x00>;
				};
			};
		};

		seclib {
			compatible = "qcom,seclib";

			lcp_dare {
				smmu_pt = <0x05>;
			};
		};
	};

	__symbols__ {
		soc = "/soc";
		buttons = "/soc/buttons";
		tlmm = "/soc/pinctrl@f100000";
		ufs = "/soc/ufs0@1D80000";
		sw = "/sw";
		pm = "/sw/pmic/pm";
		psi = "/sw/pmic/psi";
		adc = "/sw/pmic/adc";
		vadc = "/sw/pmic/adc/vadc";
		pm8550b = "/sw/pmic/adc/vadc/spmi-vadc";
		therm_table = "/sw/pmic/adc/therm_table";
		sys_therm_tb = "/sw/pmic/adc/therm_table/therm_tb1";
		pmic_die_temp_tb = "/sw/pmic/adc/therm_table/therm_tb2";
	};
};
